# STM32F302xE register map
File version: 1.0
Registers are 32-bit, read-write, reset 0x0 unless marked. A register's access mark holds for its fields unless they carry their own. Offsets are from the block's base; [hi:lo] are bit positions.

## COMP1 — Analog Comparators
Base 0x4001001C; alternate view of COMP
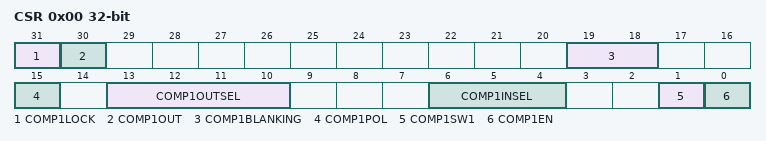
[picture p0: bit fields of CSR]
0x00 CSR — COMP control and status register
  [31] COMP1LOCK
  [30] COMP1OUT — COMP1 output level
  [19:18] COMP1BLANKING
  [15] COMP1POL — COMP1 output polarity
  [13:10] COMP1OUTSEL — COMP1 output select
  [6:4] COMP1INSEL — COMP1 inverting input select
  [1] COMP1SW1 — COMP1 SW1 switch control
  [0] COMP1EN — COMP1 enable

## COMP12_COMMON
Base 0x40010020
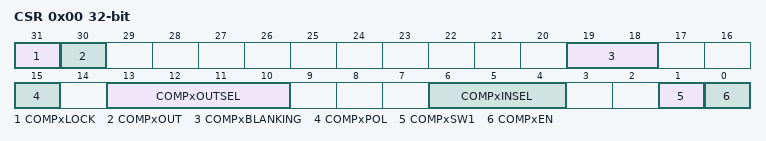
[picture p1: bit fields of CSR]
0x00 CSR — COMP control and status register, used for bits common to several COMP instances
  [31] COMPxLOCK
  [30] COMPxOUT — COMPx output level
  [19:18] COMPxBLANKING
    0=NONE (Comparator output without blanking); 1=TIM1_OC5_COMP1_2 (Comparator output blanking source TIM1 OC5 (specific to COMP instance: COMP1, COMP2)); 2=TIM2_OC3_COMP1_2 (Comparator output blanking source TIM2 OC3 (specific to COMP instance: COMP1, COMP2)); 3=TIM3_OC3_COMP1_2 (Comparator output blanking source TIM3 OC3 (specific to COMP instance: COMP1, COMP2))
  [15] COMPxPOL — COMPx output polarity
    0=NONINVERTED (COMP output polarity is not inverted: comparator output is high when the plus (non-inverting) input is at a higher voltage than the minus (inverting) input); 1=INVERTED (COMP output polarity is inverted: comparator output is low when the plus (non-inverting) input is at a lower voltage than the minus (inverting) input)
  [13:10] COMPxOUTSEL — COMPx output select
    0=NONE (COMP output is not connected to other peripherals (except GPIO and EXTI that are always connected to COMP output) (specific to COMP instance: COMP2)); 1=TIM1_BKIN (COMP output connected to TIM1 break input (BKIN)); 2=TIM1_BKIN2 (COMP output connected to TIM1 break input 2 (BKIN2)); 9=TIM2_OCCLR_COMP1_2_3 (COMP output connected to TIM2 OCREF clear. Caution: Parameter specific to COMP instances, defined with generic naming, not taking into account COMP instance constraints. Refer to literal definitions above for COMP instance constraints.); 7=TIM1_IC1_COMP1_2 (COMP output connected to TIM1 input capture 1 (specific to COMP instance: COMP2)); 8=TIM2_IC4_COMP1_2 (COMP output connected to TIM2 input capture 4 (specific to COMP instance: COMP2)); 10=TIM3_IC1_COMP1_2 (COMP output connected to TIM3 input capture 1 (specific to COMP instance: COMP2)); 6=TIM3_IC3_COMP4 (COMP output connected to TIM3 input capture 3 (specific to COMP instance: COMP4)); 11=TIM4_IC4_COMP6 (COMP output connected to TIM4 input capture 4 (specific to COMP instance: COMP6))
  [6:4] COMPxINSEL — COMPx inverting input select
    0=MINUS_1_4VREFINT (Comparator input minus connected to 1/4 VrefInt); 1=MINUS_1_2VREFINT (Comparator input minus connected to 1/2 VrefInt); 2=MINUS_3_4VREFINT (Comparator input minus connected to 3/4 VrefInt); 3=VREFINT (Comparator input minus connected to VrefInt); 4=DAC1_CH1 (Comparator input minus connected to DAC1 channel 1 (DAC_OUT1)); 6=IO1 (Comparator input minus connected to IO1 (pin PA2 for COMP2)); 7=IO2 (Comparator input minus connected to IO2 (PB12 for COMP3, PB2 for COMP4, PB10 for COMP5, PB15 for COMP6 (COMP instance availability depends on the selected device))); 5=IO3 (Comparator input minus connected to IO3 (pin PA5 for COMP1/2/3/4/5/6/7 (COMP instance availability depends on the selected device)))
  [1] COMPxSW1 — COMPx SW1 switch control
  [0] COMPxEN — COMPx enable

## COMP2 — Analog Comparators
Base 0x40010020; alternate view of COMP12_COMMON
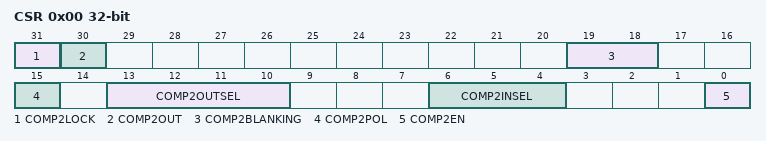
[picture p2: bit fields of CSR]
0x00 CSR — COMP control and status register
  [31] COMP2LOCK
  [30] COMP2OUT — COMP2 output level
  [19:18] COMP2BLANKING
  [15] COMP2POL — COMP2 output polarity
  [13:10] COMP2OUTSEL — COMP2 output select
  [6:4] COMP2INSEL — COMP2 inverting input select
  [0] COMP2EN — COMP2 enable

## COMP4 — Analog Comparators
Base 0x40010028
Registers as COMP2 (with COMP2 read as COMP4).

## COMP6 — Analog Comparators
Base 0x40010030
Registers as COMP2 (with COMP2 read as COMP6).
